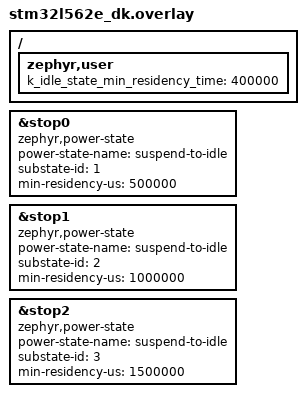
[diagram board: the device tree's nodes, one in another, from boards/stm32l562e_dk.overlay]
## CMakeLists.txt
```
# Copyright (c) 2025 Intel Corporation
# SPDX-License-Identifier: Apache-2.0

cmake_minimum_required(VERSION 3.28.0)
find_package(Zephyr REQUIRED HINTS $ENV{ZEPHYR_BASE})
project(power_states)

FILE(GLOB app_sources src/*.c)
target_sources(app PRIVATE ${app_sources})
```

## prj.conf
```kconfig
# Copyright (c) 2025 Intel Corporation
# SPDX-License-Identifier: Apache-2.0

CONFIG_PM=y
```

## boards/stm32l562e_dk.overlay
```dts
/*
 * Copyright (c) 2025 Intel Corporation
 *
 * SPDX-License-Identifier: Apache-2.0
 */
/ {
	zephyr,user {
		k_idle_state_min_residency_time = <400000>;
	};
};

&stop0 {
	compatible = "zephyr,power-state";
	power-state-name = "suspend-to-idle";
	substate-id = <1>;
	min-residency-us = <500000>;
};

&stop1 {
	compatible = "zephyr,power-state";
	power-state-name = "suspend-to-idle";
	substate-id = <2>;
	min-residency-us = <1000000>;
};

&stop2 {
	compatible = "zephyr,power-state";
	power-state-name = "suspend-to-idle";
	substate-id = <3>;
	min-residency-us = <1500000>;
};
```

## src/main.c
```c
/*
 * Copyright (c) 2025 Intel Corporation
 *
 * SPDX-License-Identifier: Apache-2.0
 */
#include <zephyr/kernel.h>

int main(void)
{
	int k_idle_min_residency_time =
		DT_PROP(DT_PATH(zephyr_user), k_idle_state_min_residency_time);
	int stop0_min_residency_time = DT_PROP(DT_NODELABEL(stop0), min_residency_us);
	int stop1_min_residency_time = DT_PROP(DT_NODELABEL(stop1), min_residency_us);
	int stop2_min_residency_time = DT_PROP(DT_NODELABEL(stop2), min_residency_us);

	while (1) {
		printk("\nGoing to k_cpu_idle.\n");
		k_usleep(k_idle_min_residency_time);
		printk("\nWake Up.\n");
		printk("\nGoing to state 0.\n");
		k_usleep(stop0_min_residency_time);
		printk("\nWake Up.\n");
		printk("\nGoing to state 1.\n");
		k_usleep(stop1_min_residency_time);
		printk("\nWake Up.\n");
		printk("\nGoing to state 2.\n");
		k_usleep(stop2_min_residency_time);
		printk("\nWake Up.\n");

		/* Anti-sleeping loop */
		while (1) {
			arch_nop();
		}
	}
	return 0;
}
```
